# SDFM register map
Vendor: Texas Instruments
Peripheral module from a debugger description file (folder UCD3138R064RSM).
Registers are 16-bit, access per field, no defined reset value unless marked. A register's access mark holds for its fields unless they carry their own. Offsets are as the file gives them; lines under a group give offsets from that group; [hi:lo] are bit positions; {n}, {i} and the like mark numbered series; 'fields as' and 'values as' point back to an identical list; <NAME> marks a mode.

## SDFM
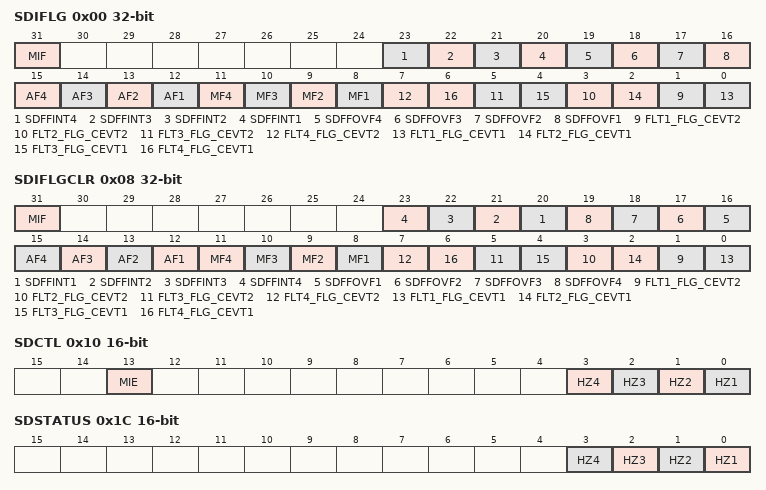
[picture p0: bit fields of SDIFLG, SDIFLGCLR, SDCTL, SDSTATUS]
0x00 SDIFLG 32-bit ro — SD Interrupt Flag Register
  [31] MIF — Set whenever any "error" interrupt (MF1-4,IFL1-4,IFH1-4,SDFFOVF1-4) is active
  [23] SDFFINT4 — SDFIFO data ready interrupt for Ch4
  [22] SDFFINT3 — SDFIFO data ready interrupt for Ch3
  [21] SDFFINT2 — SDFIFO data ready interrupt for Ch2
  [20] SDFFINT1 — SDFIFO data ready interrupt for Ch1 #br# #br#0: SDFIFO data ready interrupt has NOT occurred #br# #br#1: SDFIFO data ready interrupt has occurred
  [19] SDFFOVF4 — FIFO Overflow Flag for Ch4
  [18] SDFFOVF3 — FIFO Overflow Flag for Ch3
  [17] SDFFOVF2 — FIFO Overflow Flag for Ch2
  [16] SDFFOVF1 — FIFO Overflow Flag for Ch1 #br# #br#0 - FIFO has not overflowed #br# #br#1 - FIFO overflowed. # words received in FIFO > FIFO depth (16), NEW word is lost
  [n+11] AF{n} (n=1..4) — Acknowledge flag for Filter {n} #br# #br#0: No new data available for Filter (in non-FIFO mode) #br# #br#1: New data available for Filter (in non-FIFO mode)
  [n+7] MF{n} (n=1..4) — Modulator Failure for Filter {n} #br# #br#0: Modulator is operating normally for Filter #br# #br#1: Modulator failure for Filter
  [2n-1] FLT{n}_FLG_CEVT2 (n=1..4) — CEVT2 Interrupt flag for filter{n} #br# #br#0: CEVT2 event has not occured #br# #br#1: CEVT2 event has occurred
  [2n-2] FLT{n}_FLG_CEVT1 (n=1..4) — CEVT1 Interrupt flag for filter{n} #br# #br#0: CEVT1 event has not occured #br# #br#1: CEVT1 event has occurred
0x08 SDIFLGCLR 32-bit — SD Module Interrupt Flag Clear Bits: #br# #br#Writing a "1" will clear the respective flag bit in the SDIFLG register. #br#Writes of "0" are ignored. #br# #br#Note: If user writes a "1" to clear a bit on the same cycle that the hardware is trying to set the bit to "1", then hardware has priority and the bit will not be cleared.
  [31] MIF rw — Flag-clear bit for SDFM Master Interrupt flag. #br# #br#Writing a 1 to clear MIF flag in SDIFLG register #br# #br#Writes of "0" are ignored. #br# #br#Note: If the MIF flag is cleared and other Interrupts are still pending, MIF will again be set to 1 on the following SysClk cycle, and the INT output will be reasserted (pulsed low)
  [n+19] SDFFINT{n} rw (n=1..4) — SDFIFO data ready Interrupt flag-clear bit for Ch{n}
  [n+15] SDFFOVF{n} rw (n=1..4) — SDFIFO overflow clear Ch{n}
  [15] AF4 rw — Flag-clear bit for Acknowledge flag for Filter 4
  [14] AF3 rw — Flag Clear bit for AF3
  [13] AF2 rw — Flag Clear bit for AF2
  [12] AF1 rw — Flag Clear bit for AF1
  [n+7] MF{n} rw (n=1..4) — Flag Clear bit for MF{n}
  [2n-1] FLT{n}_FLG_CEVT2 rw (n=1..4) — Flag Clear bit for FLT{n}_FLG_CEVT2
  [2n-2] FLT{n}_FLG_CEVT1 rw (n=1..4) — Flag Clear bit for FLT{n}_FLG_CEVT1
0x10 SDCTL — SD Control Register
  [13] MIE rw — Master SDy_ERR interrupt enable #br# #br#0: SDy_ERR Interrupt and interrupt flags are disabled #br# #br#1: SDy_ERR Interrupt and interrupt flags are enabled
  [n-1] HZ{n} rw (n=1..4) — Flag Clear bit for HZ{n}
0x18 SDMFILEN — SD Master Filter Enable
  [11] MFE rw — Master Filter Enable #br# #br#0: All the four data filter units of SDFM module are disabled. All FIFOs #br# are cleared #br# #br#1: Data filter units can be enabled if bit FEN is '1'.
0x1C SDSTATUS ro
  [n-1] HZ{n} (n=1..4) — High-level Threshold crossing (Z) flag Ch{n} #br# #br#Primarily intended for detecting "zero"-crossing events. Unlike the primary comparator IFHx flag, it does not have the ability to generate an interrupt. #br# #br#0: Comparator filter output < SDCMPHZ{n}.HLTZ #br# #br#1: Comparator filter output >= SDCMPHZ{n}.HLTZ
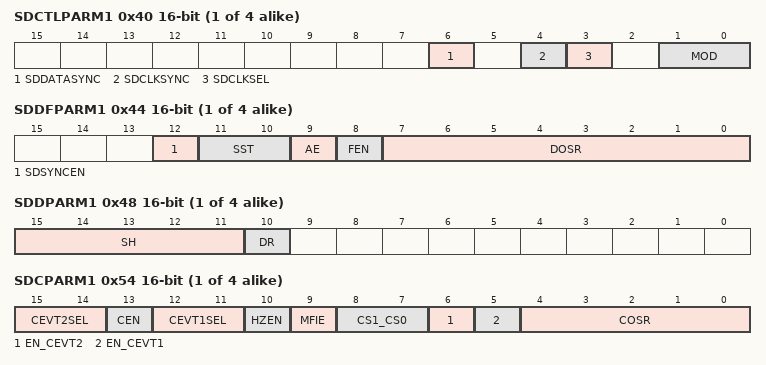
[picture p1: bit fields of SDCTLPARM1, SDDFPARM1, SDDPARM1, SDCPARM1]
{0x0+0x40*i} SDCTLPARM{i} (i=1..4) — Control Parameter Register for Ch{i}
  [6] SDDATASYNC rw — 0: SD Data is not passed through a synchronizer. #br#1: SD Data is passed through a synchronizer.
  [4] SDCLKSYNC rw — 0: SD Clock is not passed through a synchronizer. #br#1: SD Clock is passed through a synchronizer.
  [3] SDCLKSEL rw — SD{i} Clock source select. #br#0: Clock source to SDFM filter is its channel clock. #br#1: Clock source to SDFM filter is SD1 filter clock.
  [1:0] MOD rw — Modulator clock modes #br# #br#0: Mode 0: Modulator clock running at 1x data rate #br#1: Reserved #br#2: Reserved #br#3: Reserved
{0x4+0x40*i} SDDFPARM{i} (i=1..4) — Data Filter Parameter Register for Ch{i}
  [12] SDSYNCEN rw — PWM synchronization (SDSYNC) of data filter #br# #br#0: PWM synchronization of data filter is disabled #br# #br#1: PWM synchronization of data filter is enabled #br# #br#Note: SDSYNCx.SYNCSEL bits define which PWM signal is used to #br# synchronize PWMs
  [11:10] SST rw — Data filter structure #br# #br#00: Data filter runs with a Sincfast structure #br#01: Data filter runs with a Sinc1 structure #br#10: Data filter runs with a Sinc2 structure #br#11: Data filter runs with a Sinc3 structure
  [9] AE rw — Data filter Acknowledge Enable #br# #br#0: Acknowledge flag is disabled for the particular filter #br# #br#1: Acknowledge flag is enabled for the particular filter
  [8] FEN rw — Filter Enable #br# #br#0: The data filter is disabled and no data is produced #br# #br#1: The data filter is enabled and data are produced in the data filter #br# #br#Note: When filter is disabled, DOSR counter held in reset, filter data #br# erased. Also resets FIFO pointers and clears the FIFO
  [7:0] DOSR rw — Data filter Oversampling ratio #br# #br#The actual oversampling ratio of data filter is DOSR + 1 #br# #br#These bits set the oversampling ratio of the data filter. #br#0x0FF represents an oversampling ratio of 256.
{0x8+0x40*i} SDDPARM{i} (i=1..4) — Data Parameter Register for Ch{i}
  [15:11] SH rw — Shift Control #br#These bits indicate by how many bits the 16-bit window is shifted up when 16-bit data representation is chosen.
  [10] DR rw — Data filter Data representation #br# #br#0: Data stored in 16b 2's complement #br# #br#1: Data stored in 32b 2's complement
{0xC+0x40*i} SDFLT{i}CMPH1 (i=1..4) — High-level Threshold Register for Ch{i}
  [14:0] HLT rw — Unsigned high-level threshold for the comparator filter output.
{0x10+0x40*i} SDFLT{i}CMPL1 (i=1..4) — Low-level Threshold Register for Ch{i}
  [14:0] LLT rw — Unsigned low-level threshold for the comparator filter output.
{0x14+0x40*i} SDCPARM{i} rw (i=1..4) — Comparator Filter Parameter Register for Ch{i}
  [15:14] CEVT2SEL — Comparator Event2 Select #br#00: COMPL1 #br#01: COMPL1 OR COMPH1 #br#10: COMPL2 #br#11: COMPL2 OR COMPH2
  [13] CEN — Comparator Filter enable #br# #br#0: Disable comparator filter #br# #br#1: Enable comparator filter
  [12:11] CEVT1SEL — Comparator Event1 Select #br#00: COMPH1 #br#01: COMPL1 OR COMPH1 #br#10: COMPH2 #br#11: COMPL2 OR COMPH2
  [10] HZEN — High level (Z) Threshold crossing output enable #br# #br#0: Disable Higher level Threshold (Z) crossing #br#1: Enable Higher level Threhold (Z) crossing
  [9] MFIE — Modulator Failure Interrupt Enable #br# #br#0: Disable modulator failure interrupt and its flag #br# #br#1: Enable modulator failure interrupt and its flag
  [8:7] CS1_CS0 — Comparator filter structure #br# #br#00: Comparator filter runs with a sincfast structure #br#01: Comparator filter runs with a Sinc1 structure #br#10: Comparator filter runs with a Sinc2 structure #br#11: Comparator filter runs with a Sinc3 structure
  [6] EN_CEVT2 — CEVT2 interrupt enable #br# #br#0: Disable CEVT2 interrupt #br# #br#1: Enable CEVT2 interrupt
  [5] EN_CEVT1 — CEVT1 interrupt enable #br# #br#0: Disable CEVT1 interrupt #br# #br#1: Enable CEVT1 interrupt
  [4:0] COSR — Comparator Oversampling ratio. #br# #br#The actual rate is COSR + 1. #br#These bits set the oversampling ratio of the filter. #br#0x1F represents an oversampling ratio of 32
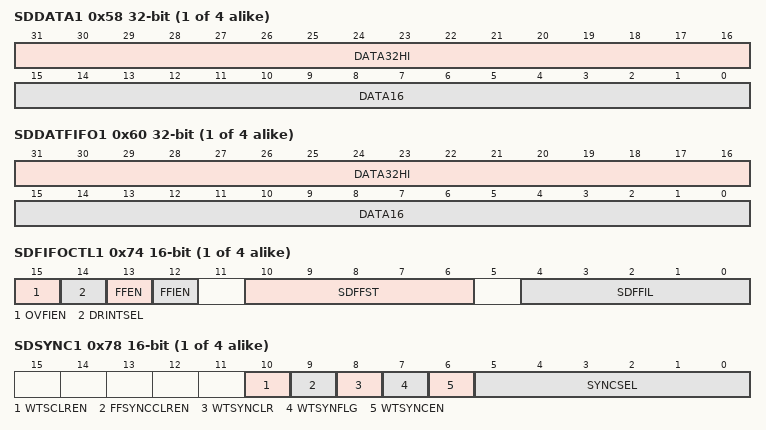
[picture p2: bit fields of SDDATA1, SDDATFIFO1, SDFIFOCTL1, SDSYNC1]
{0x18+0x40*i} SDDATA{i} 32-bit ro (i=1..4) — Data Filter Data Register (16 or 32bit) for Ch{i}
  [31:16] DATA32HI — Hi-order 16b in 32b mode, 16-bit Data in 16b mode
  [15:0] DATA16 — Lo-order 16b in 32b mode
{0x20+0x40*i} SDDATFIFO{i} 32-bit ro (i=1..4) — Filter Data FIFO Output(32b) for Ch{i}
  fields as SDDATA1
{0x28+0x40*i} SDCDATA{i} ro (i=1..4) — Comparator Filter Data Register (16b) for Ch{i}
  [15:0] DATA16 — Comparator Data output - 16b only
{0x2C+0x40*i} SDFLT{i}CMPH2 (i=1..4) — Second high level threhold for CH{i}
  [14:0] HLT2 rw — Second Unsigned high-level threshold for the comparator filter output.
{0x30+0x40*i} SDFLT{i}CMPHZ (i=1..4) — High-level (Z) Threshold Register for Ch{i}
  [14:0] HLTZ rw — Unsigned High-level threshold (Z) for the comparator filter output #br# #br#Primarily intended for detecting "zero"-crossing events. Unlike the primary comparator SDCMPHx, it does not have the ability to generate an interrupt.
{0x34+0x40*i} SDFIFOCTL{i} (i=1..4) — FIFO Control Register for Ch{i}
  [15] OVFIEN rw — SDFIFO Overflow interrupt enable #br# #br#0: SDFIFO Overflow condition will not generate an interrupt #br# #br#1: SDFIFO overflow condition generates an interrupt on SDy_ERR
  [14] DRINTSEL rw — Data-Ready Interrupt (DRINT) source select #br# #br#0 = AF{i} (Select non-FIFO data-ready interrupt) #br# #br#1 = SDFFINT{i} (Select FIFO data-ready interrupt)
  [13] FFEN rw — SDFIFO Enable #br# #br#0: Disable FIFO operation #br#1: Enable FIFO operation #br# #br#Note: When FIFO is disabled, FIFO contents are cleared
  [12] FFIEN rw — SDFIFO data ready Interrupt Enable
  [10:6] SDFFST ro — SDFIFO Status #br# #br#00000 FIFO empty #br#00001 FIFO has 1 word #br# . . . . #br#10000 FIFO has 16 words
  [4:0] SDFFIL rw — SDFIFO interrupt level bits #br# #br#The FIFO will generate an interrupt when the FIFO #br#status (SDFFST) >= FIFO level (SDFFIL )
{0x38+0x40*i} SDSYNC{i} (i=1..4) — SD Filter Sync control for Ch{i}
  [10] WTSCLREN rw — WTSYNFLG Clear-on-FIFOINT Enable #br# #br#0: WTSYNFLG can only be cleared manually (using WTSYNCLR bit) #br# #br#1: WTSYNFLG is cleared automatically on SDFFINT
  [9] FFSYNCCLREN rw — FIFO Clear-on-SDSYNC Enable #br# #br#0: SDFIFO is not automaticaly cleared upon receiving SDSYNC #br# #br#1: SDFIFO is automaticaly cleared upon receiving SDSYNC
  [8] WTSYNCLR rw — Wait-for-Sync Flag Clear (always reads 0) #br# #br#0: Write of 0 has no affect #br# #br#1: Write of 1 clears WTSYNFLG
  [7] WTSYNFLG ro — Wait-for-Sync Flag #br# #br#0: SDSYNC event has not occurred #br# #br#1: SDSYNC event occurred.
  [6] WTSYNCEN rw — Wait-for-Sync Enable #br# #br#0: Incoming Data written to SDFIFO on every Data-Ready (DR) Event #br# #br#1: Incoming Data written to SDFIFO on DR event only after SDSYNC event occurs
  [5:0] SYNCSEL rw — Defines source for the SDSYNC Input on this channel #br# #br#Refer SDSYNCx.SYNCSEL table
{0x3C+0x40*i} SDFLT{i}CMPL2 (i=1..4) — Second low level threhold for CH{i}
  [14:0] LLT2 rw — Second Unsigned low-level threshold for the comparator filter output.
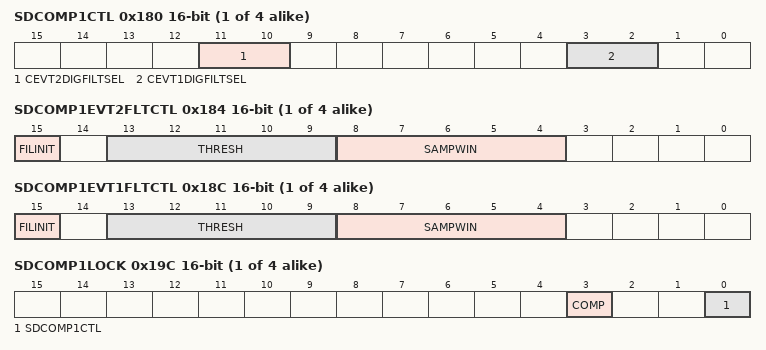
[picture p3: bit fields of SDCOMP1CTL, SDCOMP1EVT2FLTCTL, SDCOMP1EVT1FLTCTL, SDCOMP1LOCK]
{0x160+0x20*i} SDCOMP{i}CTL (i=1..4) — SD Comparator event filter{i} Control Register
  [11:10] CEVT2DIGFILTSEL rw — High comparator COMPH source select. #br# #br# 0 CEVT2 output drives COMPLOUT #br# 1 Reserved #br# 2 Output of digital filter drives COMPLOUT #br# 3 Reserved
  [3:2] CEVT1DIGFILTSEL rw — High comparator COMPH source select. #br# #br# 0 CEVT1 output drives COMPHOUT #br# 1 Reserved #br# 2 Output of digital filter drives COMPHOUT #br# 3 Reserved
{0x164+0x20*i} SDCOMP{i}EVT2FLTCTL (i=1..4) — COMPL/CEVT2 Digital filter{i} Control Register
  [15] FILINIT rw — Low filter initialization. #br# #br# 0 No effect #br# 1 Initialize all samples to the filter input value
  [13:9] THRESH rw — Low filter majority voting threshold. At least THRESH samples of the opposite state must appear within the sample window in order for the output to change state.
  [8:4] SAMPWIN rw — Low filter sample window size. Number of samples to monitor is SAMPWIN+1.
{0x168+0x20*i} SDCOMP{i}EVT2FLTCLKCTL (i=1..4) — COMPL/CEVT2 Digital filter{i} Clock Control Register
  [9:0] CLKPRESCALE rw — Low filter sample clock prescale. Number of system clocks between samples.
{0x16C+0x20*i} SDCOMP{i}EVT1FLTCTL (i=1..4) — COMPH/CEVT1 Digital filter{i} Control Register
  [15] FILINIT rw — High filter initialization. #br# #br# 0 No effect #br# 1 Initialize all samples to the filter input value
  [13:9] THRESH rw — High filter majority voting threshold. At least THRESH samples of the opposite state must appear within the sample window in order for the output to change state.
  [8:4] SAMPWIN rw — High filter sample window size. Number of samples to monitor is SAMPWIN+1.
{0x170+0x20*i} SDCOMP{i}EVT1FLTCLKCTL (i=1..4) — COMPH/CEVT1 Digital filter{i} Clock Control Register
  [9:0] CLKPRESCALE rw — High filter sample clock prescale. Number of system clocks between samples.
{0x17C+0x20*i} SDCOMP{i}LOCK (i=1..4) — SD compartor event filter{i} Lock Register
  [3] COMP rw — Lock write-access to the SDCOMP{i}EVT1/2FLTTCTL and COMP{i}FILCLKCTL registers. #br# #br# 0 SDCOMP{i}EVT1/2FLTCTL and SDCOMP{i}EVT1/2FLTCLKCTL registers are not locked. Write 0 to this bit has no effect. #br# 1 SDCOMP{i}EVT1/2FLTCTL and SDCOMP{i}EVT1/2FLTCLKCTL registers are locked. Only a system reset can clear this bit.
  [0] SDCOMP{i}CTL rw — Lock write-access to the SDCOMP{i}CTL register. #br# #br# 0 SDCOMP{i}CTL register is not locked. Write 0 to this bit has no effect. #br# 1 SDCOMP{i}CTL register is locked. Only a system reset can clear this bit.
